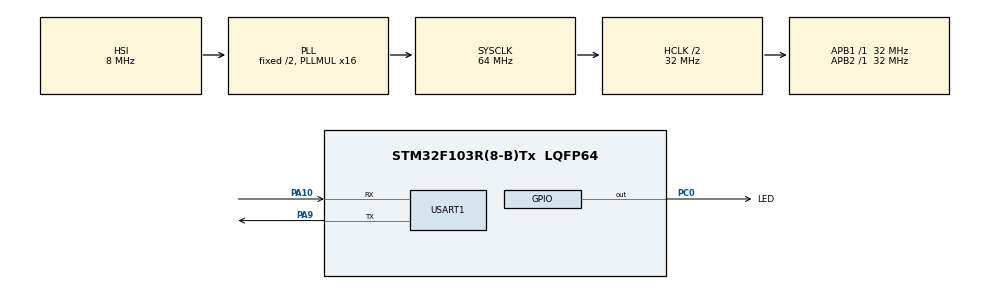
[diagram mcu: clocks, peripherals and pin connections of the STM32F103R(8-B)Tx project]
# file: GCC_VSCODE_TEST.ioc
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Mcu.Family=STM32F1
Mcu.Name=STM32F103R(8-B)Tx
Mcu.Package=LQFP64
NVIC.PriorityGroup=NVIC_PRIORITYGROUP_4
NVIC.USART1_IRQn=true\:0\:0\:false\:false\:true\:true\:true
PA10.Mode=Asynchronous
PA10.Signal=USART1_RX
PA13.Mode=Serial_Wire
PA13.Signal=SYS_JTMS-SWDIO
PA14.Mode=Serial_Wire
PA14.Signal=SYS_JTCK-SWCLK
PA9.Mode=Asynchronous
PA9.Signal=USART1_TX
PC0.GPIO_Label=LED
PC0.GPIO_Speed=GPIO_SPEED_FREQ_MEDIUM
PC0.Signal=GPIO_Output
ProjectManager.HeapSize=0x400
ProjectManager.StackSize=0x400
ProjectManager.TargetToolchain=Makefile
RCC.AHBCLKDivider=RCC_SYSCLK_DIV2
RCC.AHBFreq_Value=32000000
RCC.APB1Freq_Value=32000000
RCC.APB1TimFreq_Value=32000000
RCC.APB2Freq_Value=32000000
RCC.APB2TimFreq_Value=32000000
RCC.HCLKFreq_Value=32000000
RCC.PLLMUL=RCC_PLL_MUL16
RCC.SYSCLKFreq_VALUE=64000000
RCC.SYSCLKSource=RCC_SYSCLKSOURCE_PLLCLK
RCC.USBFreq_Value=64000000
USART1.VirtualMode=VM_ASYNC
board=custom

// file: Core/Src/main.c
/* USER CODE BEGIN Header */
/**
  ******************************************************************************
  * @file           : main.c
  * @brief          : Main program body
  ******************************************************************************
  * @attention
  *
  * <h2><center>&copy; Copyright (c) 2019 STMicroelectronics.
  * All rights reserved.</center></h2>
  *
  * This software component is licensed by ST under BSD 3-Clause license,
  * the "License"; You may not use this file except in compliance with the
  * License. You may obtain a copy of the License at:
  *                        opensource.org/licenses/BSD-3-Clause
  *
  ******************************************************************************
  */
/* USER CODE END Header */

#include "main.h"
#include "usart.h"
#include "gpio.h"
#include "cmsis_os.h"

#define APPLICATION1_TASK_STK_SIZE 512
void application1_entry(void *arg);
osThreadDef(application1_entry, osPriorityNormal, 1, APPLICATION1_TASK_STK_SIZE);

void application1_entry(void *arg)
{
  while (1)
  {
    printf("This is task1\r\n");
    HAL_GPIO_TogglePin(LEDR_GPIO_Port, LEDR_Pin);
    osDelay(300);
  }
}
#define APPLICATION2_TASK_STK_SIZE 1024
void application2_entry(void *arg);
osThreadDef(application2_entry, osPriorityNormal, 1, APPLICATION2_TASK_STK_SIZE);

void application2_entry(void *arg)
{
    float  test_f=0.35;
  while (1)
  {
    printf("This is task2\r\n");
    HAL_GPIO_TogglePin(LEDG_GPIO_Port, LEDG_Pin);
    printf("test=%.2f\r\n",test_f);
    osDelay(1500);
  }
}

// int fputc(int ch, FILE *f)
// {
//   if (ch == '\n') {
//     HAL_UART_Transmit(&huart1, (void *)"\r", 1,30000);
//   }
//   HAL_UART_Transmit(&huart1, (uint8_t *)&ch, 1, 0xFFFF);
//   return ch;
// }

int _write(int fd, char *ptr, int len)
{
    (void)HAL_UART_Transmit(&huart1, (uint8_t *)ptr, len, 0xFFFF);
    return len;
}

// int fgetc(FILE *f)
// {
//   /* Place your implementation of fgetc here */
//   /* e.g. readwrite a character to the USART2 and Loop until the end of transmission */
//   uint8_t ch = 0;
//   HAL_UART_Receive(&huart1, &ch, 1,30000);
//   return ch;
// }

void SystemClock_Config(void);

/* USER CODE BEGIN 0 */
unsigned char  hellostr[]="helloworld\r\n";
/* USER CODE END 0 */

int main(void)
{

  /* MCU Configuration--------------------------------------------------------*/

  /* Reset of all peripherals, Initializes the Flash interface and the Systick. */
  HAL_Init();

  /* Configure the system clock */
  SystemClock_Config();

  /* Initialize all configured peripherals */
  MX_GPIO_Init();
  MX_USART1_UART_Init();
  /* USER CODE BEGIN 2 */
  HAL_UART_Transmit(&huart1, hellostr, 12, 0xFFFF);
  //printf("Welcome to TencentOS tiny\r\n");
  osKernelInitialize();
  osThreadCreate(osThread(application1_entry), NULL);
  osThreadCreate(osThread(application2_entry), NULL);
  osKernelStart();
  /* USER CODE END 2 */

  /* Infinite loop */
  while (1)
  {
  HAL_Delay(1000);
  HAL_GPIO_TogglePin(LEDG_GPIO_Port, LEDG_Pin);
  printf("Welcome to TencentOS tiny\r\n");
  }
}

void SystemClock_Config(void)
{
  RCC_OscInitTypeDef RCC_OscInitStruct = {0};
  RCC_ClkInitTypeDef RCC_ClkInitStruct = {0};

  /** Initializes the CPU, AHB and APB busses clocks
  */
  RCC_OscInitStruct.OscillatorType = RCC_OSCILLATORTYPE_HSI;
  RCC_OscInitStruct.HSIState = RCC_HSI_ON;
  RCC_OscInitStruct.HSICalibrationValue = RCC_HSICALIBRATION_DEFAULT;
  RCC_OscInitStruct.PLL.PLLState = RCC_PLL_ON;
  RCC_OscInitStruct.PLL.PLLSource = RCC_PLLSOURCE_HSI_DIV2;
  RCC_OscInitStruct.PLL.PLLMUL = RCC_PLL_MUL16;
  if (HAL_RCC_OscConfig(&RCC_OscInitStruct) != HAL_OK)
  {
    Error_Handler();
  }
  /** Initializes the CPU, AHB and APB busses clocks
  */
  RCC_ClkInitStruct.ClockType = RCC_CLOCKTYPE_HCLK | RCC_CLOCKTYPE_SYSCLK | RCC_CLOCKTYPE_PCLK1 | RCC_CLOCKTYPE_PCLK2;
  RCC_ClkInitStruct.SYSCLKSource = RCC_SYSCLKSOURCE_PLLCLK;
  RCC_ClkInitStruct.AHBCLKDivider = RCC_SYSCLK_DIV2;
  RCC_ClkInitStruct.APB1CLKDivider = RCC_HCLK_DIV1;
  RCC_ClkInitStruct.APB2CLKDivider = RCC_HCLK_DIV1;

  if (HAL_RCC_ClockConfig(&RCC_ClkInitStruct, FLASH_LATENCY_2) != HAL_OK)
  {
    Error_Handler();
  }
}

void Error_Handler(void)
{
}

/************************ (C) COPYRIGHT STMicroelectronics *****END OF FILE****/
